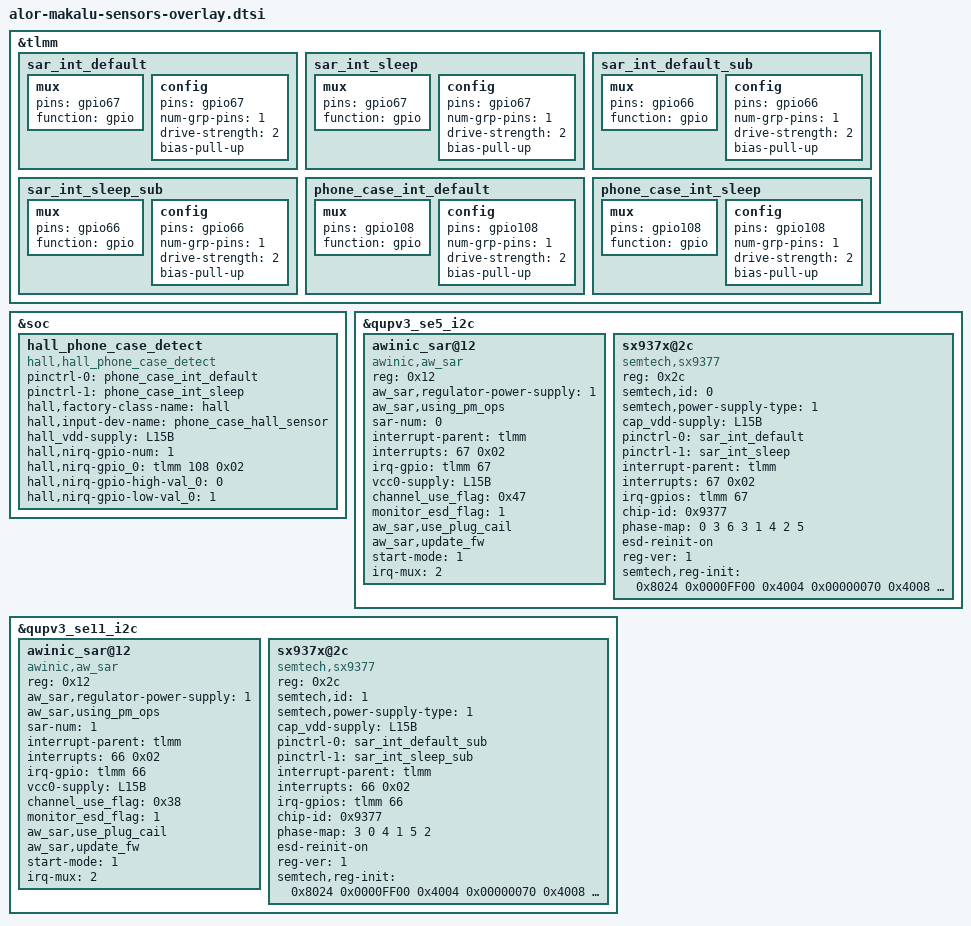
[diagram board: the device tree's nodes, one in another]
/* Copyright (c) 2025, The Linux Foundation. All rights reserved.
 *
 * This program is free software; you can redistribute it and/or modify
 * it under the terms of the GNU General Public License version 2 and
 * only version 2 as published by the Free Software Foundation.
 *
 * This program is distributed in the hope that it will be useful,
 * but WITHOUT ANY WARRANTY; without even the implied warranty of
 * MERCHANTABILITY or FITNESS FOR A PARTICULAR PURPOSE.  See the
 * GNU General Public License for more details.
 */

&tlmm {
	sar_int_default: sar_int_default {
			mux {
				pins = "gpio67";
				function =  "gpio";
			};
			config {
				pins = "gpio67";
				num-grp-pins = <1>;
				drive-strength = <2>;
				bias-pull-up;
			};
	};

	sar_int_sleep: sar_int_sleep {
			mux {
				pins = "gpio67";
				function =  "gpio";
			};
			config {
				pins = "gpio67";
				num-grp-pins = <1>;
				drive-strength = <2>;
				bias-pull-up;
			};
	};
	sar_int_default_sub: sar_int_default_sub {
			mux {
				pins = "gpio66";
				function =  "gpio";
			};
			config {
				pins = "gpio66";
				num-grp-pins = <1>;
				drive-strength = <2>;
				bias-pull-up;
			};
	};

	sar_int_sleep_sub: sar_int_sleep_sub {
			mux {
				pins = "gpio66";
				function =  "gpio";
			};
			config {
				pins = "gpio66";
				num-grp-pins = <1>;
				drive-strength = <2>;
				bias-pull-up;
			};
	};

};

&tlmm {
	phone_case_int_default: phone_case_int_default {
			mux {
				pins = "gpio108";
				function =  "gpio";
			};
			config {
				pins = "gpio108";
				num-grp-pins = <1>;
				drive-strength = <2>;
				bias-pull-up;
			};
	};

	phone_case_int_sleep: phone_case_int_sleep {
			mux {
				pins = "gpio108";
				function =  "gpio";
			};
			config {
				pins = "gpio108";
				num-grp-pins = <1>;
				drive-strength = <2>;
				bias-pull-up;
			};
	};
};

&soc {
	hall_phone_case_detect {
		compatible = "hall,hall_phone_case_detect";
		pinctrl-names = "default","sleep";
		pinctrl-0 = <&phone_case_int_default>;
		pinctrl-1 = <&phone_case_int_sleep>;
		hall,factory-class-name = "hall";
		hall,input-dev-name = "phone_case_hall_sensor";
		hall_vdd-supply = <&L15B>;
		hall,nirq-gpio-num = <1>;
		hall,nirq-gpio_0 = <&tlmm 108 0x02>;
		hall,nirq-gpio-high-val_0 = <0>;
		hall,nirq-gpio-low-val_0 = <1>;
	};
};

&qupv3_se5_i2c {
	status = "ok";
	awinic_sar@12 {
		/* common node */
		compatible = "awinic,aw_sar";
		reg = < 0x12 >;
		aw_sar,regulator-power-supply = <1>;
		aw_sar,using_pm_ops;
		sar-num = < 0 >;
		interrupt-parent = < &tlmm >;
		interrupts = <67 0x02>;
		interrupt-names = "capsense0_irq";
		irq-gpio = <&tlmm 67 0x02>;
		vcc0-supply = <&L15B>;
		channel_use_flag = <0x47>;
		monitor_esd_flag = <1>;
		aw_sar,use_plug_cail;
		aw_sar,update_fw;
		/* private node belongs to aw963xx */
		start-mode = < 1 >; // 0: start in rom  1: start in ram
		irq-mux = < 2 >; // set csx as irq pin. config this field when connect to aw96308/aw96310
		status = "okay";
	};
	sx937x@2c { /* SAR sensor */
		compatible = "semtech,sx9377";
		reg = <0x2c>;
		semtech,id = <0>;
		semtech,power-supply-type = <1>;
		cap_vdd-supply = <&L15B>;
		pinctrl-names = "default","sleep";
		pinctrl-0 = <&sar_int_default>;
		pinctrl-1 = <&sar_int_sleep>;
		interrupt-parent = <&tlmm>;
		interrupts = <67 0x02>;
		interrupt-names = "capsense0_irq";
		irq-gpios= <&tlmm 67 0x02>;

		/*chip id.
		sx933X: 0x30
		sx9371: 0x9371
		sx9372: 0x9372
		sx9373: 0x9373
		sx9374: 0x9374
		sx9375: 0x9375
		sx9376: 0x9376
		sx9377: 0x9377
		sx9378: 0x9377
		sx9379: 0x9376
		*/
		chip-id= <0x9377>;

		/*Main: Phases(aka CH) connected to the antenas for measurement
			Ref: Phases used as temperature reference correction
			Set the REF to 0xFF if there is no ref for that phase
			Multiple main phases can share the same ref
		*/
		phase-map = <
		//	Main	REF
			0       3
			6       3
			1       4
			2       5
		>;

		esd-reinit-on; //comment to disable

		reg-ver =<1>;
		semtech,reg-init = <
			0x8024 0x0000FF00
			0x4004 0x00000070
			0x4008 0x00000008
			0x42C0 0x00040800
			0x42C4 0x000000FF
			0x8020 0x00000032
			0x8028 0x46E
			0x8034 0x46E
			0x8040 0x46E
			0x804C 0x46E
			0x8058 0x46E
			0x8064 0x46E
			0x8070 0x46E
			0x807C 0x46E
			0x8030 0xFFF9FD
			0x803C 0xBFF9FF
			0x8048 0xFEF9FF
			0x8054 0xFFF9EF
			0x8060 0xF7F9FF
			0x806C 0xFFF97F
			0x8078 0xFFF9FD
			0x8084 0xFFF9FF
			0x809C 0x00006447
			0x80C0 0x00006447
			0x80E4 0x00006447
			0x812C 0x00006447
			0x8150 0x00006447
			0x8174 0x00006447
			0x8198 0x00006447
			0x8090 0x78783000
			0x80B4 0x78785000
			0x80D8 0x78785000
			0x8120 0x78785000
			0x8144 0x78785000
			0x8168 0x78785000
			0x818C 0x78785000
			0x8094 0x00805000
			0x80B8 0x00805000
			0x80DC 0x00805000
			0x8100 0x14800000
			0x8124 0x00805000
			0x8148 0x00805000
			0x816C 0x00805000
			0x8190 0x00805000
			0x8088 0x00100000
			0x80AC 0x00100000
			0x80D0 0x00100000
			0x80F4 0x00100000
			0x8118 0x00100000
			0x813C 0x00100000
			0x8160 0x00100000
			0x8184 0x00100000
			0x808C 0x60200030
			0x80B0 0x60200030
			0x80D4 0x60200030
			0x80F8 0x20601800
			0x811C 0x60200030
			0x8140 0x60200030
			0x8164 0x60200030
			0x8188 0x60200030
			0x802C 0x006C81B2
			0x8038 0x00548152
			0x8044 0x00510144
			0x805C 0x006F81BE
			0x8068 0x002EC0BB
			0x8074 0x004DC137
			0x8080 0x003200C8
			0x8024 0x0000FFFF
			0x4280 0x0000000F
		>;
		status = "ok";
	};
};

&qupv3_se11_i2c {
	status = "ok";
	awinic_sar@12 {
		/* common node */
		compatible = "awinic,aw_sar";
		reg = < 0x12 >;
		aw_sar,regulator-power-supply = <1>;
		aw_sar,using_pm_ops;
		sar-num = < 1 >;
		interrupt-parent = < &tlmm >;
		interrupts = <66 0x02>;
		interrupt-names = "capsense1_irq";
		irq-gpio = <&tlmm 66 0x02>;
		vcc0-supply = <&L15B>;
		channel_use_flag = <0x38>;
		monitor_esd_flag = <1>;
		aw_sar,use_plug_cail;
		aw_sar,update_fw;
		/* private node belongs to aw963xx */
		start-mode = < 1 >; // 0: start in rom  1: start in ram
		irq-mux = < 2 >; // set csx as irq pin. config this field when connect to aw96308/aw96310
		status = "okay";
	};
	sx937x@2c { /* SAR sensor */
		compatible = "semtech,sx9377";
		reg = <0x2c>;
		semtech,id = <1>;
		semtech,power-supply-type = <1>;
		cap_vdd-supply = <&L15B>;
		pinctrl-names = "default","sleep";
		pinctrl-0 = <&sar_int_default_sub>;
		pinctrl-1 = <&sar_int_sleep_sub>;
		interrupt-parent = <&tlmm>;
		interrupts = <66 0x02>;
		interrupt-names = "capsense1_irq";
		irq-gpios= <&tlmm 66 0x02>;

		/*chip id.
		sx933X: 0x30
		sx9371: 0x9371
		sx9372: 0x9372
		sx9373: 0x9373
		sx9374: 0x9374
		sx9375: 0x9375
		sx9376: 0x9376
		sx9377: 0x9377
		sx9378: 0x9377
		sx9379: 0x9376
		*/
		chip-id= <0x9377>;

		/*Main: Phases(aka CH) connected to the antenas for measurement
			Ref: Phases used as temperature reference correction
			Set the REF to 0xFF if there is no ref for that phase
			Multiple main phases can share the same ref
		*/
		phase-map = <
		//	Main	REF
			3       0
			4       1
			5       2
		>;

		esd-reinit-on; //comment to disable

		reg-ver =<1>;
		semtech,reg-init = <
			0x8024 0x0000FF00
			0x4004 0x00000070
			0x4008 0x00000008
			0x42C0 0x00040800
			0x42C4 0x000000FF
			0x8020 0x00000032
			0x8028 0x456
			0x8034 0x456
			0x8040 0x456
			0x804C 0x456
			0x8058 0x456
			0x8064 0x456
			0x8070 0x456
			0x807C 0x456
			0x8030 0xFFF97F
			0x803C 0xF7F9FF
			0x8048 0xFFF9EF
			0x8054 0xFFD9FF
			0x8060 0xBFF9FF
			0x806C 0xFFF9FD
			0x8078 0xFFF9FD
			0x8084 0xFFF9FF
			0x809C 0x00006447
			0x80C0 0x00006447
			0x80E4 0x00006447
			0x812C 0x00006447
			0x8150 0x00006447
			0x8174 0x00006447
			0x8198 0x00006447
			0x8090 0x78783000
			0x80B4 0x78785000
			0x80D8 0x78785000
			0x8120 0x78785000
			0x8144 0x78785000
			0x8168 0x78785000
			0x818C 0x78785000
			0x8094 0x00805000
			0x80B8 0x00805000
			0x80DC 0x00805000
			0x8100 0x14800000
			0x8124 0x00805000
			0x8148 0x00805000
			0x816C 0x00805000
			0x8190 0x00805000
			0x8088 0x00100000
			0x80AC 0x00100000
			0x80D0 0x00100000
			0x80F4 0x00100000
			0x8118 0x00100000
			0x813C 0x00100000
			0x8160 0x00100000
			0x8184 0x00100000
			0x808C 0x60200030
			0x80B0 0x60200030
			0x80D4 0x60200030
			0x80F8 0x20601800
			0x811C 0x60200030
			0x8140 0x60200030
			0x8164 0x60200030
			0x8188 0x60200030
			0x802C 0x006C81B2
			0x8038 0x00548152
			0x8044 0x00510144
			0x805C 0x006F81BE
			0x8068 0x002EC0BB
			0x8074 0x004DC137
			0x8080 0x003200C8
			0x8024 0x0000FFFF
			0x4280 0x0000000F
		>;
		status = "ok";
	};
};

